# HC32F467 register map
File version: 1.0
CPU: CM4 r0p1, little endian, MPU, FPU, 4 interrupt priority bits
Registers are 32-bit, read-write, reset 0x0 unless marked. A register's access mark holds for its fields unless they carry their own. Offsets are from the block's base; lines under a group give offsets from that group; [hi:lo] are bit positions; {n}, {i} and the like mark numbered series; 'fields as' and 'values as' point back to an identical list; <NAME> marks a mode.

## Memory map
0x00000400 ICG size 0x10
0x40008000 AES size 0x40
0x40008400 HASH size 0x80
0x40008C00 CRC size 0x100
0x40009000 CAN1 size 0xCA — desc CAN
0x40010400 EFM size 0x1B0
0x40010600 OTS size 0x3A20C
0x40010800 AOS size 0x174
0x40017C00 EMB0 size 0x1C — desc EMB
0x40017C20 EMB1 size 0x1C — desc EMB
0x40017C40 EMB2 size 0x1C — desc EMB
0x40017C60 EMB3 size 0x1C — desc EMB
0x40017C80 EMB4 size 0x1C — desc EMB
0x40017CA0 EMB5 size 0x1C — desc EMB
0x40017CC0 EMB6 size 0x1C — desc EMB
0x40018000 TMR61 size 0x1A0 — desc TMR6
0x40018300 TMR6_COMMON size 0x100
0x40018400 TMR62 size 0x1A0 — desc TMR6
0x40018800 TMR63 size 0x1A0 — desc TMR6
0x4001C000 SPI1 size 0x1C — desc SPI
0x4001C400 SPI2 size 0x1C — desc SPI
0x4001C800 SPI3 size 0x1C — desc SPI
0x4001CC00 USART1 size 0x1C — desc USART
0x4001D000 USART2 size 0x1C — desc USART
0x4001D400 USART3 size 0x1C — desc USART
0x4001D800 USART4 size 0x1C — desc USART
0x4001DC00 USART5 size 0x20 — desc USART
0x4001E000 I2S1 size 0x1C — desc I2S
0x4001E400 I2S2 size 0x1C — desc I2S
0x40020000 SPI4 size 0x1C — desc SPI
0x40020400 SPI5 size 0x1C — desc SPI
0x40020800 SPI6 size 0x1C — desc SPI
0x40020C00 USART6 size 0x1C
0x40021000 USART7 size 0x1C — desc USART
0x40021C00 USART10 size 0x20
0x40022000 I2S3 size 0x1C — desc I2S
0x40022400 I2S4 size 0x1C — desc I2S
0x40024000 TMR01 size 0x18 — desc TMR0
0x40024400 TMR02 size 0x18 — desc TMR0
0x40026000 TMRA5 size 0x150 — desc TMRA
0x40026400 TMRA6 size 0x150 — desc TMRA
0x40026800 TMRA7 size 0x150 — desc TMRA
0x40026C00 TMRA8 size 0x150 — desc TMRA
0x40038000 TMR41 size 0xE6 — desc TMR4
0x40038400 TMR42 size 0xE6 — desc TMR4
0x40038800 TMR43 size 0xE6 — desc TMR4
0x4003A000 TMRA1 size 0x150 — desc TMRA
0x4003A400 TMRA2 size 0x150 — desc TMRA
0x4003A800 TMRA3 size 0x150 — desc TMRA
0x4003AC00 TMRA4 size 0x150 — desc TMRA
0x40040000 ADC1 size 0xC5
0x40040400 ADC2 size 0xC5
0x40040800 ADC3 size 0xB1
0x40041000 DAC1 size 0x1E — desc DAC
0x40042000 TRNG size 0x14
0x40048000 PWC size 0xC400
0x40048400 FCM size 0x24
0x40049000 WDT size 0xC
0x40049400 SWDT size 0xC
0x40049C00 CTC size 0xC
0x4004A000 CMP1 size 0xA — desc CMP
0x4004A010 CMP2 size 0xA — desc CMP
0x4004A400 CMP3 size 0xA — desc CMP
0x4004C000 RTC size 0x60
0x4004C400 CMU size 0x7D08
0x4004CC00 RMU size 0x100
0x4004E000 I2C1 size 0x34 — desc I2C
0x4004E400 I2C2 size 0x34 — desc I2C
0x4004E800 I2C3 size 0x34 — desc I2C
0x40050000 ETH size 0x11058
0x40050000 MPU size 0xA0
0x40050800 SRAMC size 0x14
0x40050C00 KEYSCAN size 0xC
0x40051000 INTC size 0x2B4
0x40053000 DMA1 size 0x238 — desc DMA
0x40053400 DMA2 size 0x238 — desc DMA
0x40053800 GPIO size 0x638
0x40055000 MAU size 0x18
0x40055400 PERIC size 0x2C
0x40055800 DVP size 0x30
{0x40055C00+0x400*n} DCU{n} size 0x1C (n=1..8) — desc DCU
0x40058000 FMAC1 size 0x64 — desc FMAC
0x40058400 FMAC2 size 0x64 — desc FMAC
0x40058800 FMAC3 size 0x64 — desc FMAC
0x40058C00 FMAC4 size 0x64 — desc FMAC
0x40070000 SDIOC1 size 0x54 — desc SDIOC
0x40078000 CAN2 size 0xCA — desc CAN
0x40078400 SDIOC2 size 0x54 — desc SDIOC
0x40080000 USBFS size 0xE04
0x400C0000 USBHS size 0xE04
0x88000000 SMC size 0x210
0x88000400 DMC size 0x304
0x88100000 NFC size 0x8180
0x9C000000 QSPI size 0x808
0xE0042000 DBGC size 0x2C

## ADC1
Base 0x40040000
0x00 STR 8-bit
  [0] STRT
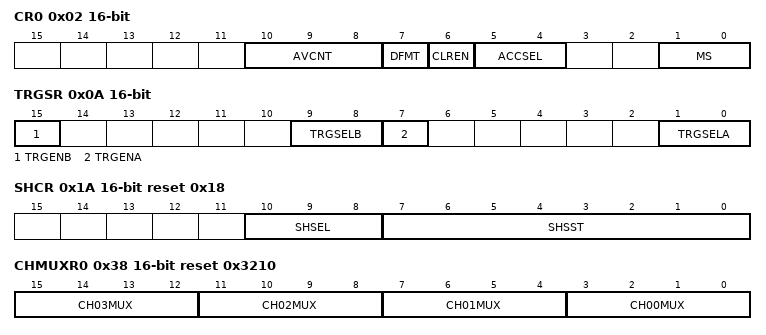
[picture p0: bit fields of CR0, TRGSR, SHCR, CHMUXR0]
0x02 CR0 16-bit
  [10:8] AVCNT, [7] DFMT, [6] CLREN, [5:4] ACCSEL, [1:0] MS
0x04 CR1 16-bit
  [2] RSCHSEL
0x0A TRGSR 16-bit
  [15] TRGENB, [9:8] TRGSELB, [7] TRGENA, [1:0] TRGSELA
0x0C CHSELRA
  [15:0] CHSELA
0x10 CHSELRB
  [15:0] CHSELB
0x14 AVCHSELR
  [15:0] AVCHSEL
0x18 EXCHSELR 8-bit
  [0] EXCHSEL
0x1A SHCR 16-bit reset 0x18
  [10:8] SHSEL, [7:0] SHSST
{0x20+i} SSTR{i} 8-bit reset 0xB (i=0..15)
0x38 CHMUXR0 16-bit reset 0x3210
  [4n+3:4n] CH{n:02}MUX (n=0..3)
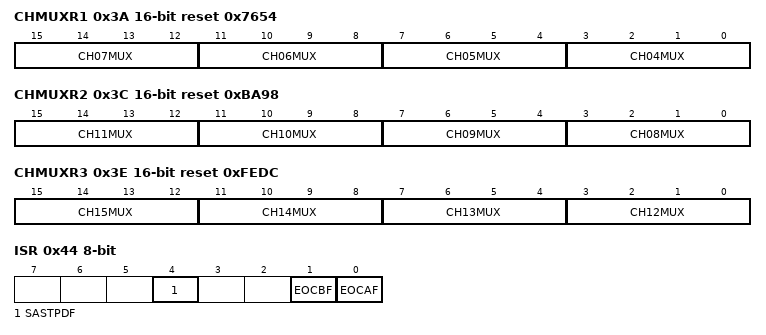
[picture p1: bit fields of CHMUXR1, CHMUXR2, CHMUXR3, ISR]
0x3A CHMUXR1 16-bit reset 0x7654
  [4n-13:4n-16] CH{n:02}MUX (n=4..7)
0x3C CHMUXR2 16-bit reset 0xBA98
  [4n-29:4n-32] CH{n:02}MUX (n=8..11)
0x3E CHMUXR3 16-bit reset 0xFEDC
  [4n-45:4n-48] CH{n}MUX (n=12..15)
0x44 ISR 8-bit ro
  [4] SASTPDF, [1] EOCBF, [0] EOCAF
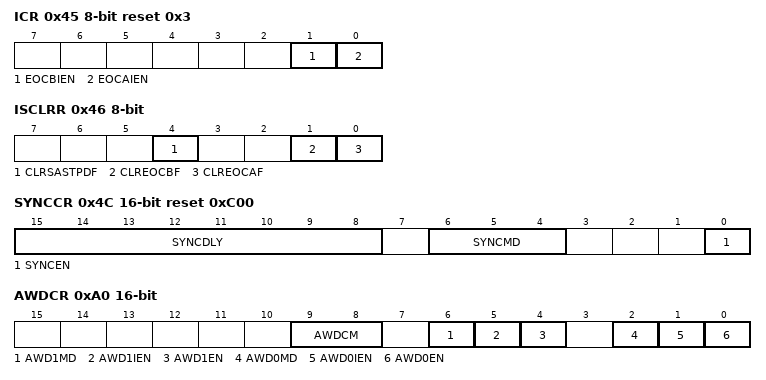
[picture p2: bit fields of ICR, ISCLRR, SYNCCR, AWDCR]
0x45 ICR 8-bit reset 0x3
  [1] EOCBIEN, [0] EOCAIEN
0x46 ISCLRR 8-bit
  [4] CLRSASTPDF, [1] CLREOCBF, [0] CLREOCAF
0x4C SYNCCR 16-bit reset 0xC00
  [15:8] SYNCDLY, [6:4] SYNCMD, [0] SYNCEN
{0x50+2i} DR{i} 16-bit ro (i=0..15)
0xA0 AWDCR 16-bit
  [9:8] AWDCM, [6] AWD1MD, [5] AWD1IEN, [4] AWD1EN, [2] AWD0MD, [1] AWD0IEN, [0] AWD0EN
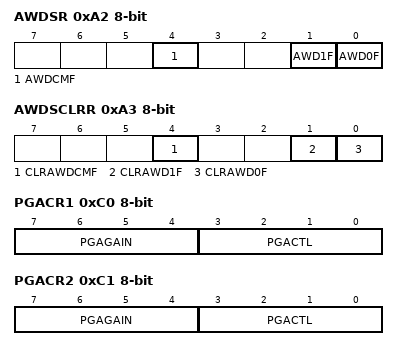
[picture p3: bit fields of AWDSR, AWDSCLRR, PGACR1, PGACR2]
0xA2 AWDSR 8-bit ro
  [4] AWDCMF, [1] AWD1F, [0] AWD0F
0xA3 AWDSCLRR 8-bit wo
  [4] CLRAWDCMF, [1] CLRAWD1F, [0] CLRAWD0F
0xA4 AWD0DR0 16-bit
0xA6 AWD0DR1 16-bit reset 0xFFFF
0xA8 AWD0CHSR 8-bit
  [4:0] AWDCH
0xAC AWD1DR0 16-bit
0xAE AWD1DR1 16-bit reset 0xFFFF
0xB0 AWD1CHSR 8-bit
  [4:0] AWDCH
0xC0 PGACR1 8-bit
  [7:4] PGAGAIN, [3:0] PGACTL
0xC1 PGACR2 8-bit
  [7:4] PGAGAIN, [3:0] PGACTL
0xC4 PGAVSSENR 8-bit
  [2:0] PGAVSSEN

## ADC2
Base 0x40040400
Same registers: ADC3 0x40040800
Registers as ADC1, without SHCR, SYNCCR, PGACR1, PGACR2, PGAVSSENR; these are added or differ:
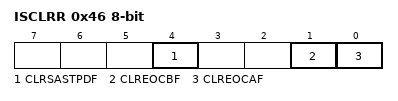
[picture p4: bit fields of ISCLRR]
0x46 ISCLRR 8-bit wo
  [4] CLRSASTPDF, [1] CLREOCBF, [0] CLREOCAF
